# STM32N645xx register map
File version: 1.0
Registers are 32-bit, read-write, reset 0x0 unless marked. A register's access mark holds for its fields unless they carry their own. Offsets are from the block's base; [hi:lo] are bit positions; {n}, {i} and the like mark numbered series; 'fields as' and 'values as' point back to an identical list.

## DCMIPP
Base 0x48002000
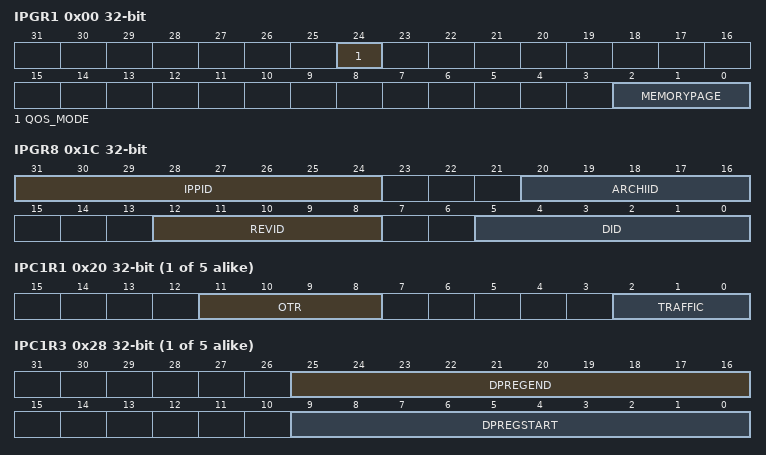
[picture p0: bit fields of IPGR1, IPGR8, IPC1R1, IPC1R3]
0x00 IPGR1 — DCMIPP IPPLUG global register 1
  [24] QOS_MODE — Quality of service
  [2:0] MEMORYPAGE — Memory page size, as power of 2 of 64-byte units:
0x04 IPGR2 — DCMIPP IPPLUG global register 2
  [0] PSTART — Request to lock the IP-Plug, to allow reconfiguration
0x08 IPGR3 — DCMIPP IPPLUG global register 3
  [0] IDLE — Status of IP-Plug
0x1C IPGR8 — DCMIPP IPPLUG identification register
  [31:24] IPPID — IP identifier (0xAA)
  [20:16] ARCHIID — Architecture identifier (0x04)
  [12:8] REVID — Revision identifier (0x03)
  [5:0] DID — Division identifier (0x14)
{0x10+0x10*i} IPC{i}R1 (i=1..5) — DCMIPP IPPLUG Clientx register 1
  [11:8] OTR — max outstanding transactions:
  [2:0] TRAFFIC — Burst size as power of 2 of 8 bytes units
{0x14+0x10*i} IPC{i}R2 (i=1..5) — DCMIPP IPPLUG Clientx register 2
  [19:16] WLRU — Ratio for WLRU[3:0] arbitration:
{0x18+0x10*i} IPC{i}R3 (i=1..5) — DCMIPP IPPLUG Clientx register 3
  [25:16] DPREGEND — End word (AXI width = 64 bits) of the FIFO of this client
  [9:0] DPREGSTART — Start word (AXI width = 64 bits) of the FIFO of this client
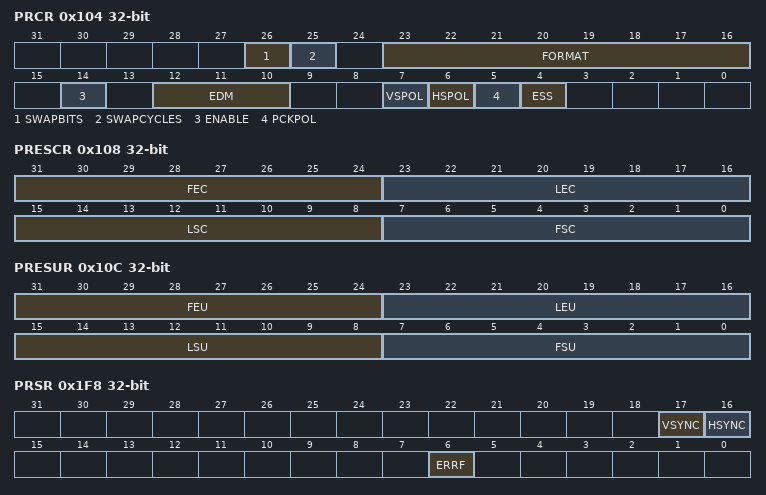
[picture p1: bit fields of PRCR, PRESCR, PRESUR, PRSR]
0x104 PRCR — DCMIPP parallel interface control register
  [26] SWAPBITS — Swap LSB vs
  [25] SWAPCYCLES — Swap data from cycle 0 vs
  [23:16] FORMAT — Other values: Data is captured and output as-is through the data/dump pipeline only (e
  [14] ENABLE — Parallel interface enable
  [12:10] EDM — Extended data mode
  [7] VSPOL — Vertical synchronization polarity
  [6] HSPOL — Horizontal synchronization polarity
  [5] PCKPOL — Pixel clock polarity
  [4] ESS — Embedded synchronization select
0x108 PRESCR — DCMIPP parallel interface embedded synchronization code register
  [31:24] FEC — Frame end delimiter code
  [23:16] LEC — Line end delimiter code
  [15:8] LSC — Line start delimiter code
  [7:0] FSC — Frame start delimiter code
0x10C PRESUR — DCMIPP parallel interface embedded synchronization unmask register
  [31:24] FEU — Frame end delimiter unmask
  [23:16] LEU — Line end delimiter unmask
  [15:8] LSU — Line start delimiter unmask
  [7:0] FSU — Frame start delimiter unmask
0x1F4 PRIER — DCMIPP parallel interface interrupt enable register
  [6] ERRIE — Synchronization error interrupt enable
0x1F8 PRSR — DCMIPP parallel interface status register
  [17] VSYNC — This bit gives the state of the VSYNC pin with the correct programmed polarity if the ENABLE bit is
  [16] HSYNC — This bit gives the state of the HSYNC pin with the correct programmed polarity if the ENABLE bit is
  [6] ERRF — Synchronization error raw interrupt status
0x1FC PRFCR — DCMIPP parallel interface interrupt clear register
  [6] CERRF — Synchronization error interrupt status clear
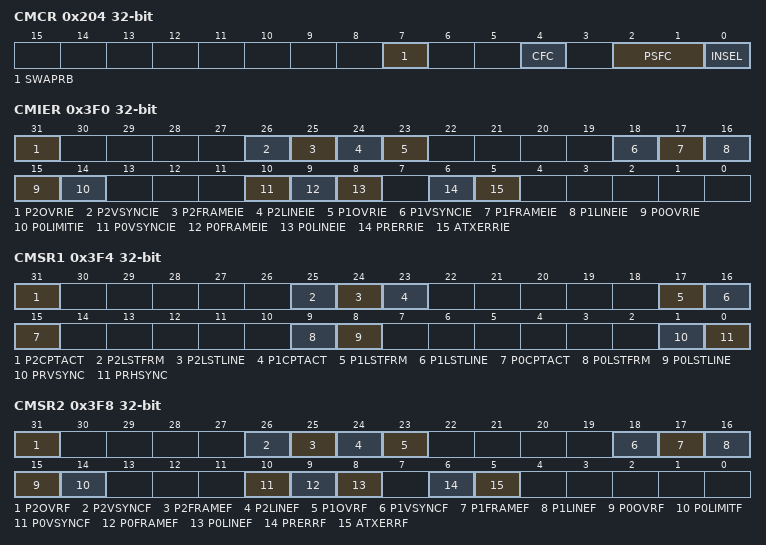
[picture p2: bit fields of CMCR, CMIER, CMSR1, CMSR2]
0x204 CMCR — DCMIPP common configuration register
  [7] SWAPRB — Swap R/U and B/V
  [4] CFC — Clear frame counter
  [2:1] PSFC — Pipe selection for the frame counter
  [0] INSEL — input selection
0x208 CMFRCR — DCMIPP common frame counter register
  [31:0] FRMCNT — Frame counter, read-only, loops around
0x3F0 CMIER — DCMIPP common interrupt enable register
  [31] P2OVRIE — Overrun interrupt status enable for the Pipe2
  [26] P2VSYNCIE — Vertical sync interrupt enable for the Pipe2
  [25] P2FRAMEIE — Frame Capture complete interrupt enable for the Pipe2
  [24] P2LINEIE — multi-Line Capture complete interrupt enable for the Pipe2
  [23] P1OVRIE — Overrun interrupt enable for the Pipe1
  [18] P1VSYNCIE — Vertical sync interrupt enable for the Pipe1
  [17] P1FRAMEIE — Frame Capture complete interrupt enable for the Pipe1
  [16] P1LINEIE — multi-Line Capture complete interrupt status clear for the Pipe1
  [15] P0OVRIE — Overrun interrupt enable for the Pipe0
  [14] P0LIMITIE — limit interrupt enable for the Pipe0
  [10] P0VSYNCIE — Vertical sync interrupt enable for the Pipe0
  [9] P0FRAMEIE — Frame Capture complete interrupt enable for the Pipe0
  [8] P0LINEIE — multi-Line Capture complete interrupt enable for the Pipe0
  [6] PRERRIE — limit interrupt enable for the Parallel Interface
  [5] ATXERRIE — AXI Transfer error interrupt enable for IPPLUG
0x3F4 CMSR1 — DCMIPP common status register 1
  [31] P2CPTACT — Active frame capture (active from start-of-frame to frame complete) for Pipe2
  [25] P2LSTFRM — Last frame LSB bit, sampled at frame capture complete event for Pipe2
  [24] P2LSTLINE — Last line LSB bit, sampled at Frame capture complete event for Pipe2
  [23] P1CPTACT — Active frame capture (active from start-of-frame to frame complete) for Pipe1
  [17] P1LSTFRM — Last frame LSB bit, sampled at frame capture complete event for Pipe1
  [16] P1LSTLINE — Last Line LSB bit, sampled at Frame capture complete event for Pipe1
  [15] P0CPTACT — Active frame capture (active from start-of-frame to frame complete) for Pipe0
  [9] P0LSTFRM — Last frame LSB bit, sampled at Frame capture complete event for Pipe0
  [8] P0LSTLINE — Last Line LSB bit, sampled at Frame capture complete event for Pipe0
  [1] PRVSYNC — This bit gives the state of the VSYNC pin with the correct programmed polarity on the parallel inte
  [0] PRHSYNC — This bit gives the state of the HSYNC pin with the correct programmed polarity on the parallel inte
0x3F8 CMSR2 — DCMIPP common status register 2
  [31] P2OVRF — Overrun raw interrupt status for Pipe2
  [26] P2VSYNCF — VSYNC raw interrupt status for Pipe2
  [25] P2FRAMEF — Frame capture completed raw interrupt status for Pipe2
  [24] P2LINEF — Multi-line capture completed raw interrupt status for Pipe2
  [23] P1OVRF — Overrun raw interrupt status for Pipe1
  [18] P1VSYNCF — VSYNC raw interrupt status for Pipe1
  [17] P1FRAMEF — Frame capture completed raw interrupt status for Pipe1
  [16] P1LINEF — Multi-line capture completed raw interrupt status for Pipe1
  [15] P0OVRF — Overrun raw interrupt status for Pipe0
  [14] P0LIMITF — Limit raw interrupt status for Pipe0
  [10] P0VSYNCF — VSYNC raw interrupt status for Pipe0
  [9] P0FRAMEF — Frame capture completed raw interrupt status for Pipe0
  [8] P0LINEF — Multi-line capture completed raw interrupt status for Pipe0
  [6] PRERRF — Synchronization error raw interrupt status for the parallel interface
  [5] ATXERRF — AXI transfer error interrupt status flag for the IPPLUG
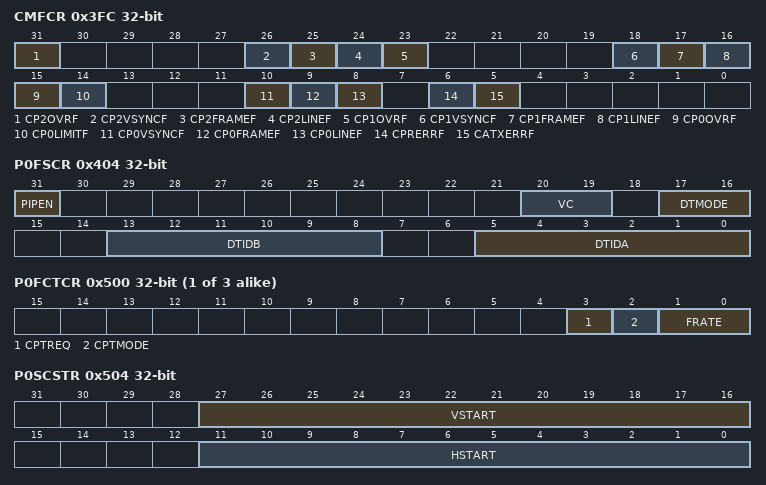
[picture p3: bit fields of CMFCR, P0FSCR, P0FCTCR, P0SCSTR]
0x3FC CMFCR — DCMIPP common interrupt clear register
  [31] CP2OVRF — Overrun interrupt status clear
  [26] CP2VSYNCF — Vertical synchronization interrupt status clear
  [25] CP2FRAMEF — Frame capture complete interrupt status clear
  [24] CP2LINEF — Multi-line capture complete interrupt status clear
  [23] CP1OVRF — Overrun interrupt status clear
  [18] CP1VSYNCF — Vertical synchronization interrupt status clear
  [17] CP1FRAMEF — Frame capture complete interrupt status clear
  [16] CP1LINEF — Multi-line capture complete interrupt status clear
  [15] CP0OVRF — Overrun interrupt status clear
  [14] CP0LIMITF — limit interrupt status clear
  [10] CP0VSYNCF — Vertical synchronization interrupt status clear
  [9] CP0FRAMEF — Frame capture complete interrupt status clear
  [8] CP0LINEF — Multi-line capture complete interrupt status clear
  [6] CPRERRF — Synchronization error interrupt status clear
  [5] CATXERRF — AXI Transfer error interrupt status clear
0x404 P0FSCR — DCMIPP Pipe0 flow selection configuration register
  [31] PIPEN — Activation of PipeN
  [20:19] VC — Flow selection mode
  [17:16] DTMODE — Flow selection mode
  [13:8] DTIDB — Data type selection ID B
  [5:0] DTIDA — Data type selection ID A
{0x500+0x400*i} P{i}FCTCR (i=0..2) — DCMIPP Pipe{i} flow control configuration register
  [3] CPTREQ — Capture requested
  [2] CPTMODE — Capture mode
  [1:0] FRATE — Frame capture rate control
0x504 P0SCSTR — DCMIPP Pipe0 stat/crop start register
  [27:16] VSTART — Vertical start, from 0 to 4094 pixels high
  [11:0] HSTART — Horizontal start, from 0 to 4094 words wide
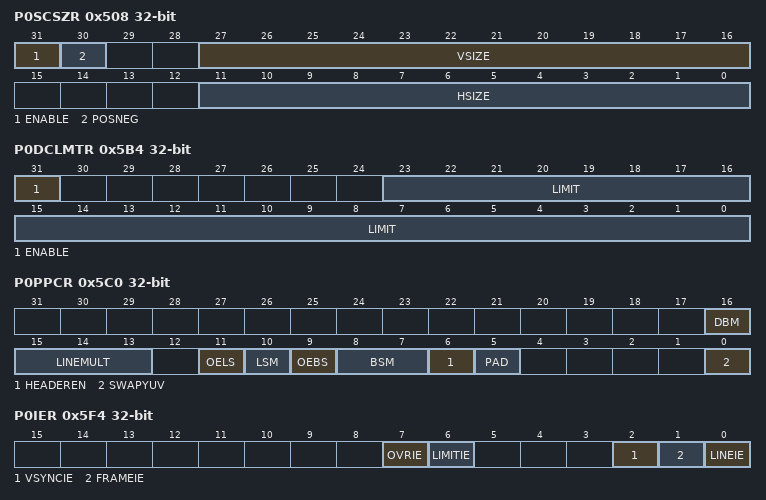
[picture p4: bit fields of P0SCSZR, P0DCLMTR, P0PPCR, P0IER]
0x508 P0SCSZR — DCMIPP Pipe0 stat/crop size register
  [31] ENABLE — This bit is set and cleared by software
  [30] POSNEG — This bit is set and cleared by software
  [27:16] VSIZE — Vertical size, from 0 to 4094 pixels high
  [11:0] HSIZE — Horizontal size, from 0 to 4094 word wide (data 32-bit)
0x5B0 P0DCCNTR — DCMIPP Pipe0 dump counter register
  [25:0] CNT — Number of data dumped during the frame
0x5B4 P0DCLMTR — DCMIPP Pipe0 dump limit register
  [31] ENABLE
  [23:0] LIMIT — Maximum number of 32-bit data that can be dumped during a frame, after the crop 2D operation
0x5C0 P0PPCR — DCMIPP Pipe0 pixel packer configuration register
  [16] DBM — Double buffer mode
  [15:13] LINEMULT — Amount of capture completed lines for LINE Event and Interrupt
  [11] OELS — Odd/even line select (line select start)
  [10] LSM — Line select mode
  [9] OEBS — Odd/even byte select (byte select start)
  [8:7] BSM — Byte select mode
  [6] HEADEREN — CSI header dump enable
  [5] PAD — Pad mode for monochrome and raw Bayer 10/12/14 bpp: MSB vs
  [0] SWAPYUV — SwapY vs UV bits, when the YUV mode is active
0x5C4 P0PPM0AR1 — DCMIPP Pipe0 pixel packer Memory0 address register 1
  [31:0] M0A — Memory0 address
0x5C8 P0PPM0AR2 — DCMIPP Pipe0 pixel packer Memory0 address register 2
  [31:0] M0A — Memory0 address
0x5D0 P0STM0AR — DCMIPP Pipe0 status Memory0 address register
0x5F4 P0IER — DCMIPP Pipe0 interrupt enable register
  [7] OVRIE — Overrun interrupt enable
  [6] LIMITIE — Limit interrupt enable
  [2] VSYNCIE — VSYNC interrupt enable
  [1] FRAMEIE — Frame capture completed interrupt enable
  [0] LINEIE — Multi-line capture completed interrupt enable
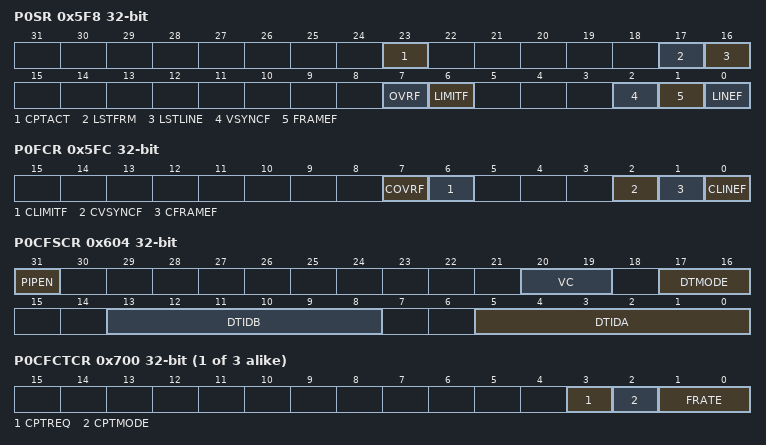
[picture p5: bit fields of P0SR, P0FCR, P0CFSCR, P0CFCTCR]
0x5F8 P0SR — DCMIPP Pipe0 status register
  [23] CPTACT — Capture immediate status
  [17] LSTFRM — Last frame LSB bit, sampled at frame capture complete event
  [16] LSTLINE — Last line LSB bit, sampled at frame capture complete event
  [7] OVRF — Overrun raw interrupt status
  [6] LIMITF — Limit raw interrupt status
  [2] VSYNCF — VSYNC raw interrupt status
  [1] FRAMEF — Frame capture completed raw interrupt status
  [0] LINEF — Multi-line capture completed raw interrupt status
0x5FC P0FCR — DCMIPP Pipe0 interrupt clear register
  [7] COVRF — Overrun interrupt status clear
  [6] CLIMITF — limit interrupt status clear
  [2] CVSYNCF — Vertical synchronization interrupt status clear
  [1] CFRAMEF — Frame capture complete interrupt status clear
  [0] CLINEF — Multi-line capture complete interrupt status clear
0x604 P0CFSCR — DCMIPP Pipe0 current flow selection configuration register
  [31] PIPEN — Current activation of PipeN
  [20:19] VC — Current flow selection mode
  [17:16] DTMODE — Flow selection mode
  [13:8] DTIDB — Current Data type selection ID B
  [5:0] DTIDA — Current Data type selection ID A
{0x700+0x400*i} P{i}CFCTCR (i=0..2) — DCMIPP Pipe{i} current flow control configuration register
  fields as P0FCTCR
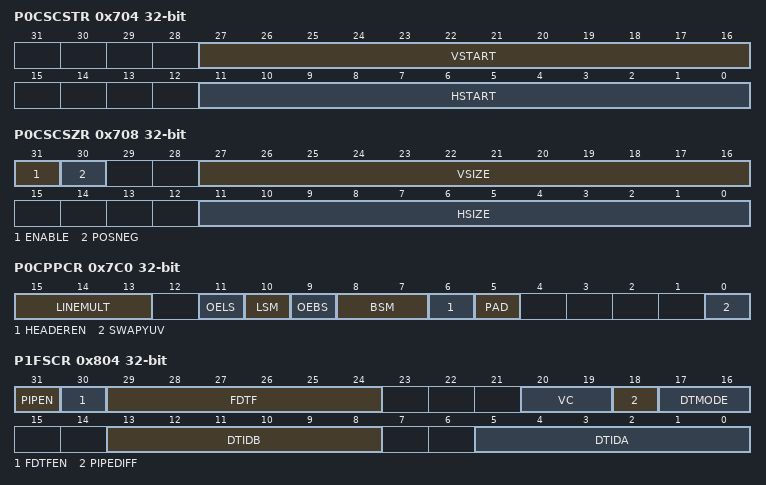
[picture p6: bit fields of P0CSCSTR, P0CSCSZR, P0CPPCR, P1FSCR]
0x704 P0CSCSTR — DCMIPP Pipe0 current stat/crop start register
  [27:16] VSTART — Current vertical start, from 0 to 4094 pixels high
  [11:0] HSTART — Current horizontal start, from 0 to 4094 words wide
0x708 P0CSCSZR — DCMIPP Pipe0 current stat/crop size register
  [31] ENABLE — Current value of the ENABLE bit
  [30] POSNEG — Current value of the POSNEG bit
  [27:16] VSIZE — Current vertical size, from 0 to 4094 pixels high
  [11:0] HSIZE — Current horizontal size, from 0 to 4094 word wide (data 32-bit)
0x7C0 P0CPPCR — DCMIPP Pipe0 current pixel packer configuration register
  [15:13] LINEMULT — Current amount of capture completed lines for LINE Event and Interrupt
  [11] OELS — Current odd/even line select (Line select start)
  [10] LSM — Current Line select mode
  [9] OEBS — Current odd/even byte select (Byte select start)
  [8:7] BSM — Current Byte select mode
  [6] HEADEREN — Current CSI header dump enable
  [5] PAD — Current Pad mode for monochrome and raw Bayer 10/12/14 bpp: MSB vs
  [0] SWAPYUV — SwapY vs UV bits, when the YUV mode is active
{0x7C4+0x400*i} P{i}CPPM0AR1 (i=0..2) — DCMIPP Pipe{i} current pixel packer Memory0 address register 1
  [31:0] M0A — Memory0 address
0x7C8 P0CPPM0AR2 — DCMIPP Pipe0 current pixel packer Memory0 address register 2
0x804 P1FSCR — DCMIPP Pipe1 flow selection configuration register
  [31] PIPEN — Activation of PipeN
  [30] FDTFEN — Force Data type format enable
  [29:24] FDTF — Force Data type format
  [20:19] VC — Flow selection mode
  [18] PIPEDIFF — Differentiates Pipe2 vs
  [17:16] DTMODE — Flow selection mode
  [13:8] DTIDB — Data type ID B
  [5:0] DTIDA — Data type ID A
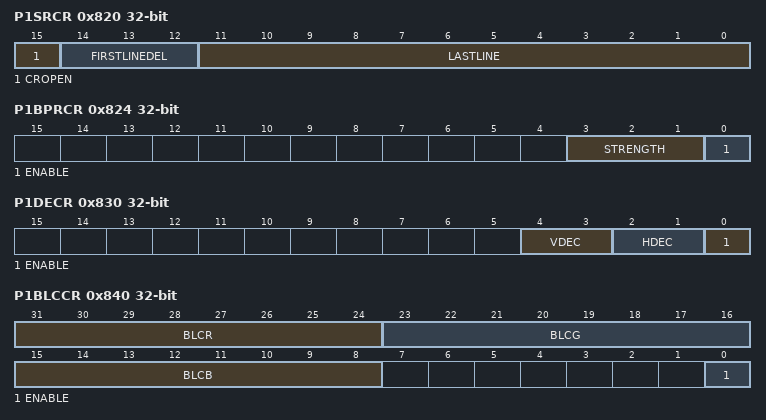
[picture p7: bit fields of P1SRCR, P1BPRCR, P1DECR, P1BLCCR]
0x820 P1SRCR — DCMIPP Pipe1 stat removal configuration register
  [15] CROPEN — Crop line enable
  [14:12] FIRSTLINEDEL — Number of lines to be deleted when CROPEN = 1
  [11:0] LASTLINE — Number of the last line to be kept when CROPEN = 1
0x824 P1BPRCR — DCMIPP Pipe1 bad pixel removal control register
  [3:1] STRENGTH — Strength (aggressivity) of the bad pixel detection:
  [0] ENABLE — Bad pixel detection must be enabled only for raw Bayer flows, as it corrupts RGB flows
0x828 P1BPRSR — DCMIPP Pipe1 bad pixel removal status register
  [11:0] BADCNT — Amount of detected bad pixels
0x830 P1DECR — DCMIPP Pipe1 decimation register
  [4:3] VDEC — Vertical decimation ratio
  [2:1] HDEC — Horizontal decimation ratio
  [0] ENABLE
0x840 P1BLCCR — DCMIPP Pipe1 black level calibration control register
  [31:24] BLCR — Black level calibration - Red
  [23:16] BLCG — Black level calibration - Green
  [15:8] BLCB — Black level calibration - Blue
  [0] ENABLE — Black level calibration
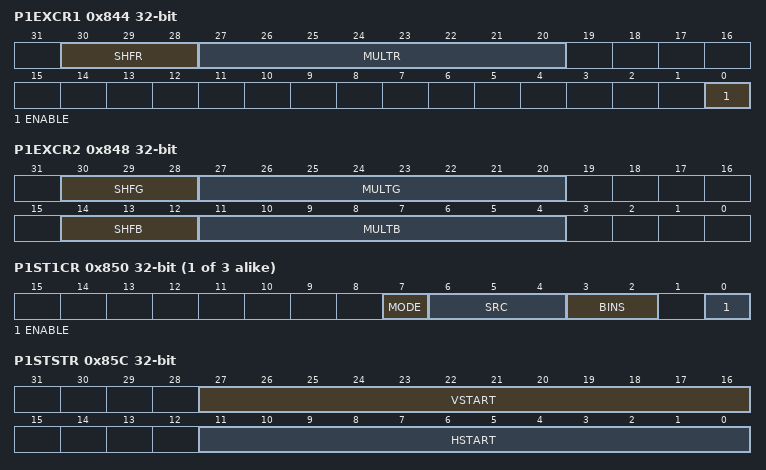
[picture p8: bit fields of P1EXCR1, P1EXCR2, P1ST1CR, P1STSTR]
0x844 P1EXCR1 — DCMIPP Pipe1 exposure control register 1
  [30:28] SHFR — Exposure shift - Red
  [27:20] MULTR — Exposure multiplier - Red
  [0] ENABLE — Exposure control (multiplication and shift) of all red, green and blue
0x848 P1EXCR2 — DCMIPP Pipe1 exposure control register 2
  [30:28] SHFG — Exposure shift - Green
  [27:20] MULTG — Exposure multiplier - Green
  [14:12] SHFB — Exposure shift - Blue
  [11:4] MULTB — Exposure multiplier - Blue
{0x84C+4i} P1ST{i}CR (i=1..3) — DCMIPP Pipe1 statistics {i} control register
  [7] MODE — Statistics mode
  [6:4] SRC — Statistics source
  [3:2] BINS — Bin definition
  [0] ENABLE
0x85C P1STSTR — DCMIPP Pipe1 statistics window start register
  [27:16] VSTART — Vertical start, from 0 to 4094 pixels high
  [11:0] HSTART — Horizontal start, from 0 to 4094 pixels wide
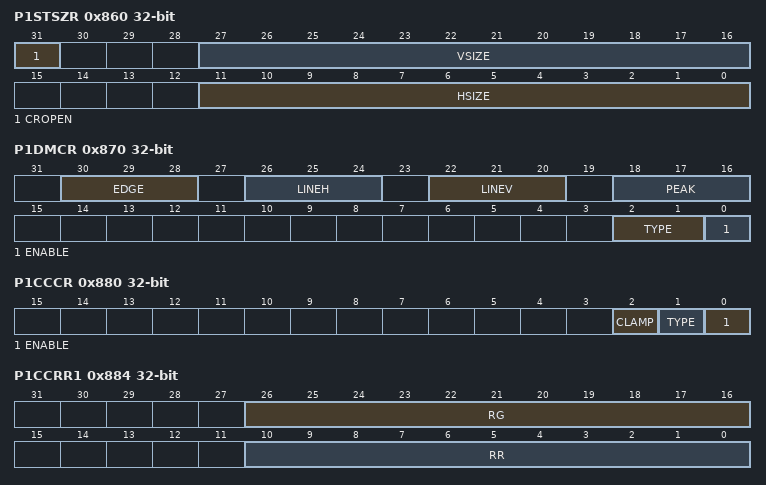
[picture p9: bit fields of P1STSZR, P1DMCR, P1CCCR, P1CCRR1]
0x860 P1STSZR — DCMIPP Pipe1 statistics window size register
  [31] CROPEN
  [27:16] VSIZE — Vertical size, from 0 to 4094 pixels high
  [11:0] HSIZE — Horizontal size, from 0 to 4094 pixels wide
0x864 P1ST1SR — DCMIPP Pipe1 statistics 1 status register
  [23:0] ACCU — Accumulation result, divided by 256
0x868 P1ST2SR — DCMIPP Pipe1 statistics 2 status register
  [23:0] ACCU — accumulation result, divided by 256
0x86C P1ST3SR — DCMIPP Pipe1 statistics 3 status register
  [23:0] ACCU — accumulation result, divided by 256
0x870 P1DMCR — DCMIPP Pipe1 demosaicing configuration register
  [30:28] EDGE — Strength of the edge detection
  [26:24] LINEH — Strength of the horizontal line detection
  [22:20] LINEV — Strength of the vertical line detection
  [18:16] PEAK — Strength of the peak detection
  [2:1] TYPE — Raw Bayer type
  [0] ENABLE
0x880 P1CCCR — DCMIPP Pipe1 ColorConv configuration register
  [2] CLAMP — Clamp the output samples
  [1] TYPE — output samples type used while CLAMP is activated
  [0] ENABLE
0x884 P1CCRR1 — DCMIPP Pipe1 ColorConv red coefficient register 1
  [26:16] RG — Coefficient row 1 column 2 of the matrix
  [10:0] RR — Coefficient row 1 column 1 of the matrix
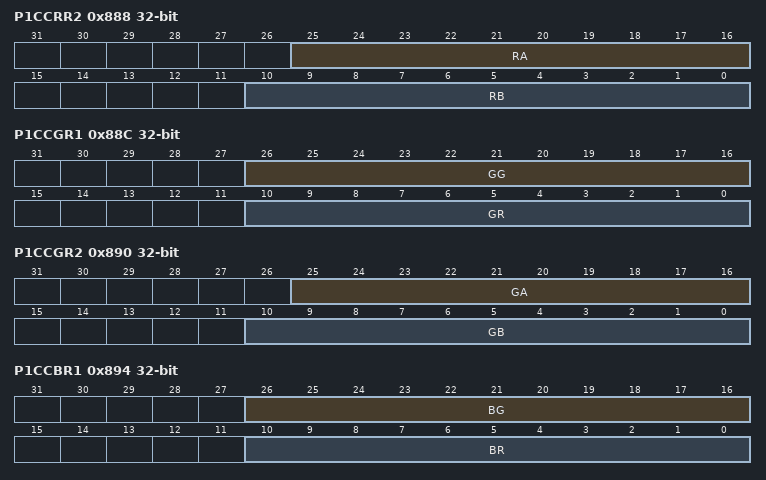
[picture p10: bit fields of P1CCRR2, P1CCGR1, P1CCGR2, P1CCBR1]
0x888 P1CCRR2 — DCMIPP Pipe1 ColorConv red coefficient register 2
  [25:16] RA — Coefficient row 1 of the added column (signed integer value)
  [10:0] RB — Coefficient row 1 column 3 of the matrix
0x88C P1CCGR1 — DCMIPP Pipe1 ColorConv green coefficient register 1
  [26:16] GG — Coefficient row 2 column 2 of the matrix
  [10:0] GR — Coefficient row 2 column 1 of the matrix
0x890 P1CCGR2 — DCMIPP Pipe1 ColorConv green coefficient register 2
  [25:16] GA — Coefficient row 2 of the added column (signed integer value)
  [10:0] GB — Coefficient row 2 column 3 of the matrix
0x894 P1CCBR1 — DCMIPP Pipe1 ColorConv blue coefficient register 1
  [26:16] BG — Coefficient row 3 column 2 of the matrix
  [10:0] BR — Coefficient row 3 column 1 of the matrix
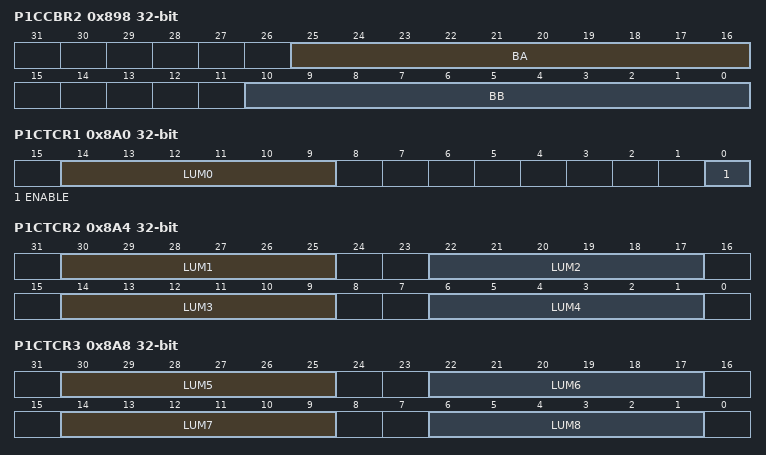
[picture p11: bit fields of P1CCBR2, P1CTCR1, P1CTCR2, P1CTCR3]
0x898 P1CCBR2 — DCMIPP Pipe1 ColorConv blue coefficient register 2
  [25:16] BA — Coefficient row 3 of the added column (signed integer value)
  [10:0] BB — Coefficient row 3 column 3 of the matrix
0x8A0 P1CTCR1 — DCMIPP Pipe1 contrast control register 1
  [14:9] LUM0 — Luminance increase for input luminance of 0 (increase is idle with LUMx = 16)
  [0] ENABLE
0x8A4 P1CTCR2 — DCMIPP Pipe1 contrast control register 2
  [38-8n:33-8n] LUM{n} (n=1..4) — Luminance increase for input luminance of {32n} (increase is idle with LUMx = 16)
0x8A8 P1CTCR3 — DCMIPP Pipe1 contrast control register 3
  [70-8n:65-8n] LUM{n} (n=5..8) — Luminance increase for input luminance of {32n} (increase is idle with LUMx = 16)
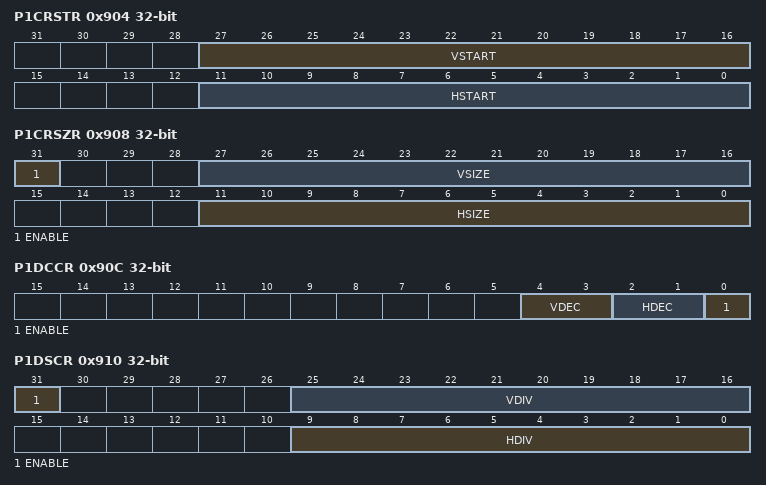
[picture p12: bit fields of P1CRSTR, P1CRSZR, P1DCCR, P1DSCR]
0x904 P1CRSTR — DCMIPP Pipe1 crop window start register
  fields as P1STSTR
0x908 P1CRSZR — DCMIPP Pipe1 crop window size register
  [31] ENABLE
  [27:16] VSIZE — Vertical size, from 0 to 4094 pixels high
  [11:0] HSIZE — Horizontal size, from 0 to 4094 pixels wide
0x90C P1DCCR — DCMIPP Pipe1 decimation register
  [4:3] VDEC — Vertical decimation ratio
  [2:1] HDEC — Horizontal decimation ratio
  [0] ENABLE — Decimation enable
0x910 P1DSCR — DCMIPP Pipe1 downsize configuration register
  [31] ENABLE — Downscaler Enable
  [25:16] VDIV — Vertical division factor, from 128 (8x) to 1023 (1x)
  [9:0] HDIV — Horizontal division factor, from 128 (8x) to 1023 (1x)
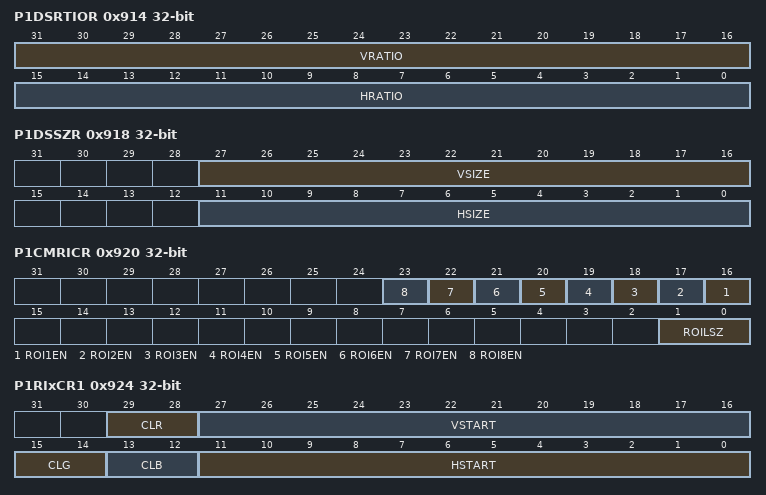
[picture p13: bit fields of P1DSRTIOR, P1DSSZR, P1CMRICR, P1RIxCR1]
0x914 P1DSRTIOR — DCMIPP Pipe1 downsize ratio register
  [31:16] VRATIO — Vertical ratio, from 8192 (1x) to 65535 (8x)
  [15:0] HRATIO — Horizontal ratio, from 8192 (1x) to 65535 (8x)
0x918 P1DSSZR — DCMIPP Pipe1 downsize destination size register
  [27:16] VSIZE — Vertical size, from 0 to 4094 pixels high
  [11:0] HSIZE — Horizontal size, from 0 to 4094 pixels wide
0x920 P1CMRICR — DCMIPP Pipe1 common ROI configuration register
  [n+15] ROI{n}EN (n=1..8) — Region Of Interest {n} Enable
  [1:0] ROILSZ — Region of interest line size width
0x924 P1RIxCR1 — DCMIPP Pipe1 ROIx configuration register 1
  [29:28] CLR — Color line red
  [27:16] VSTART — Vertical start
  [15:14] CLG — Color line green
  [13:12] CLB — Color line blue
  [11:0] HSTART — Horizontal start
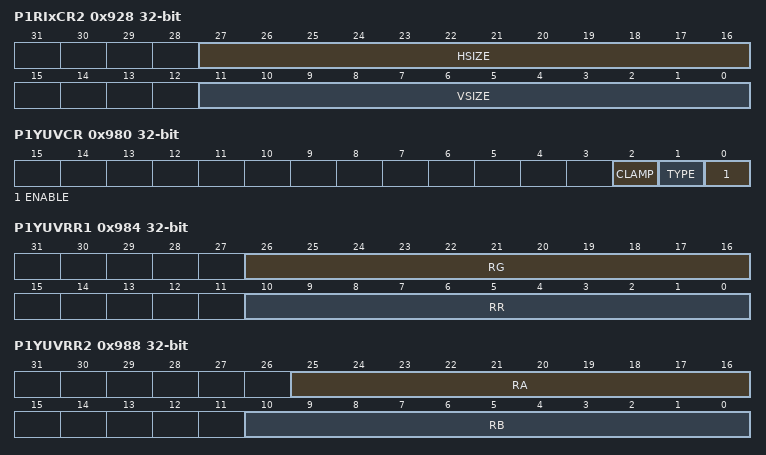
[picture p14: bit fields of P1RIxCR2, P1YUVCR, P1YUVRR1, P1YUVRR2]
0x928 P1RIxCR2 — DCMIPP Pipe1 ROIx configuration register 2
  [27:16] HSIZE — Horizontal Size
  [11:0] VSIZE — Vertical Size
0x970 P1GMCR — DCMIPP Pipe1 gamma configuration register
  [0] ENABLE — Gamma enable
0x980 P1YUVCR — DCMIPP Pipe1 YUVConv configuration register
  [2] CLAMP — Clamp the output samples
  [1] TYPE — Output samples type used while CLAMP is activated
  [0] ENABLE
0x984 P1YUVRR1 — DCMIPP Pipe1 YUVConv red coefficient register 1
  fields as P1CCRR1
0x988 P1YUVRR2 — DCMIPP Pipe1 YUVConv red coefficient register 2
  fields as P1CCRR2
0x98C P1YUVGR1 — DCMIPP Pipe1 YUVConv green coefficient register 1
  fields as P1CCGR1
0x990 P1YUVGR2 — DCMIPP Pipe1 YUVConv green coefficient register 2
  fields as P1CCGR2
0x994 P1YUVBR1 — DCMIPP Pipe1 YUVConv blue coefficient register 1
  fields as P1CCBR1
0x998 P1YUVBR2 — DCMIPP Pipe1 YUV blue coefficient register 2
  fields as P1CCBR2
0x9C0 P1PPCR — DCMIPP Pipe1 pixel packer configuration register
  [20] LMAWE — Line multi address wrapping enable
  [19:17] LMAWM — Line multi address wrapping modulo
  [16] DBM — Double buffer mode
  [15:13] LINEMULT — Amount of capture completed lines for LINE Event and Interrupt
  [4] SWAPRB — Swaps R-vs-B components if RGB, and U-vs-V components if YUV
  [3:0] FORMAT — Memory format
0x9C4 P1PPM0AR1 — DCMIPP Pipe1 pixel packer Memory0 address register 1
  [31:0] M0A — Memory0 address register 1
0x9C8 P1PPM0AR2 — DCMIPP Pipe1 pixel packer Memory0 address register 2
  [31:0] M0A — Memory0 address register 2
0x9CC P1PPM0PR — DCMIPP Pipe1 pixel packer Memory0 pitch register
  [14:0] PITCH — Number of bytes between the address of two consecutive lines
0x9D0 P1STM0AR — DCMIPP Pipe1 status Memory0 address register
0x9D4 P1PPM1AR1 — DCMIPP Pipe1 pixel packer Memory1 address register 1
  [31:0] M1A — Memory1 address
0x9D8 P1PPM1AR2 — DCMIPP Pipe1 pixel packer Memory1 address register 2
  [31:0] M1A — Memory1 address
0x9DC P1PPM1PR — DCMIPP Pipe1 pixel packer Memory1 pitch register
  fields as P1PPM0PR
0x9E0 P1STM1AR — DCMIPP Pipe1 status Memory1 address register
  [14:0] M1A — status Memory1 address register
0x9E4 P1PPM2AR1 — DCMIPP Pipe1 pixel packer memory2 address register 1
  [31:0] M2A — Memory2 address register 1
0x9E8 P1PPM2AR2 — DCMIPP Pipe1 pixel packer memory2 address register 2
  [31:0] M2A — Memory2 address register 2
0x9F0 P1STM2AR — DCMIPP Pipe1 status Memory2 address register
  [31:0] M2A — status Memory2 address register
0x9F4 P1IER — DCMIPP Pipe1 interrupt enable register
  [7] OVRIE — Overrun interrupt enable
  [2] VSYNCIE — VSYNC interrupt enable
  [1] FRAMEIE — Frame capture completed interrupt enable
  [0] LINEIE — Multi-line capture completed interrupt enable
0x9F8 P1SR — DCMIPP Pipe1 status register
  [23] CPTACT — Capture immediate status
  [17] LSTFRM — Last frame LSB bit, sampled at frame capture complete event
  [16] LSTLINE — Last line LSB bit, sampled at frame capture complete event
  [7] OVRF — Overrun raw interrupt status
  [2] VSYNCF — VSYNC raw interrupt status
  [1] FRAMEF — Frame capture completed raw interrupt status
  [0] LINEF — Multi-line capture completed raw interrupt status
0x9FC P1FCR — DCMIPP Pipe1 interrupt clear register
  [7] COVRF — Overrun interrupt status clear
  [2] CVSYNCF — Vertical synchronization interrupt status clear
  [1] CFRAMEF — Frame capture complete interrupt status clear
  [0] CLINEF — Multi-line capture complete interrupt status clear
0xA04 P1CFSCR — DCMIPP Pipe1 current flow selection configuration register
  [31] PIPEN — Current activation of PipeN
  [30] FDTFEN — Current force Data type format enable
  [29:24] FDTF — Current force Data type format
  [20:19] VC — Current flow selection mode
  [18] PIPEDIFF — Current differentiates Pipe2 vs
  [17:16] DTMODE — Flow selection mode
  [13:8] DTIDB — Current Data type ID B
  [5:0] DTIDA — Current Data type ID A
0xA24 P1CBPRCR — DCMIPP Pipe1 current bad pixel removal register
  [3:1] STRENGTH — Current strength (aggressivity) of the bad pixel detection:
  [0] ENABLE — Current status of enable bit
0xA40 P1CBLCCR — DCMIPP Pipe1 current black level calibration control register
  [31:24] BLCR — Current black level calibration - Red
  [23:16] BLCG — Current black level calibration - Green
  [15:8] BLCB — Current black level calibration - Blue
  [0] ENABLE — For current black level calibration
0xA44 P1CEXCR1 — DCMIPP Pipe1 current exposure control register 1
  [30:28] SHFR — Current exposure shift - Red
  [27:20] MULTR — Current exposure multiplier - Red
  [0] ENABLE — for exposure control (multiplication and shift)
0xA48 P1CEXCR2 — DCMIPP Pipe1 current exposure control register 2
  [30:28] SHFG — Current exposure shift - Green
  [27:20] MULTG — Current exposure multiplier - Green
  [14:12] SHFB — Current exposure shift - Blue
  [11:4] MULTB — Current exposure multiplier - Blue
0xA50 P1CST1CR — DCMIPP Pipe1 current statistics 1 control register
  [31:8] ACCU — Current accumulation result, divided by 256
  [7] MODE — Current statistics mode
  [6:4] SRC — Current source of statistics
  [3:2] BINS — Current bin definition
  [0] ENABLE — Current enable bit value
0xA54 P1CST2CR — DCMIPP Pipe1 current statistics 2 control register
  [31:8] ACCU — Accumulation result, divided by 256
  [7] MODE — statistics mode
  [6:4] SRC — source of stat
  [3:2] BINS — Bin definition
  [0] ENABLE
0xA58 P1CST3CR — DCMIPP Pipe1 current statistics 3 control register
  [31:8] ACCU — Accumulation result, divided by 256
  [7] MODE — Statistics mode
  [6:4] SRC — Statistics source
  [3:2] BINS — Bin definition
  [0] ENABLE
0xA5C P1CSTSTR — DCMIPP Pipe1 current statistics window start register
  [27:16] VSTART — Current vertical start, from 0 to 4094 pixels high
  [11:0] HSTART — Current horizontal start, from 0 to 4094 pixels wide
0xA60 P1CSTSZR — DCMIPP Pipe1 current statistics window size register
  [31] CROPEN — Current CROPEN bit value
  [27:16] VSIZE — Current vertical size, from 0 to 4094 pixels high
  [11:0] HSIZE — Current horizontal size, from 0 to 4094 pixels wide
0xA80 P1CCCCR — DCMIPP Pipe1 current ColorConv configuration register
  [2] CLAMP — Clamp the output samples
  [1] TYPE — output samples type used while CLAMP is activated
  [0] ENABLE — This bit indicates the current value applied
0xA84 P1CCCRR1 — DCMIPP Pipe1 current ColorConv red coefficient register 1
  [26:16] RG — Current coefficient row 1 column 2 of the matrix
  [10:0] RR — Current coefficient row 1 column 1 of the matrix
0xA88 P1CCCRR2 — DCMIPP Pipe1 current ColorConv red coefficient register 2
  [25:16] RA — Current coefficient row 1 of the added column (signed integer value)
  [10:0] RB — Current coefficient row 1 column 3 of the matrix
0xA8C P1CCCGR1 — DCMIPP Pipe1 current ColorConv green coefficient register 1
  [26:16] GG — Current coefficient row 2 column 2 of the matrix
  [10:0] GR — Current coefficient row 2 column 1 of the matrix
0xA90 P1CCCGR2 — DCMIPP Pipe1 current ColorConv green coefficient register 2
  [25:16] GA — Current coefficient row 2 of the added column (signed integer value)
  [10:0] GB — Current coefficient row 2 column 3 of the matrix
0xA94 P1CCCBR1 — DCMIPP Pipe1 current ColorConv blue coefficient register 1
  [26:16] BG — Current coefficient row 3 column 2 of the matrix
  [10:0] BR — Current coefficient row 3 column 1 of the matrix
0xA98 P1CCCBR2 — DCMIPP Pipe1 current ColorConv blue coefficient register 2
  [25:16] BA — Current coefficient row 3 of the added column (signed integer value)
  [10:0] BB — Current coefficient row 3 column 3 of the matrix
0xAA0 P1CCTCR1 — DCMIPP Pipe1 current contrast control register 1
  [14:9] LUM0 — Current luminance increase for input luminance of 0 (increase is idle with LUMx = 16)
  [0] ENABLE — Current ENABLE bit value
0xAA4 P1CCTCR2 — DCMIPP Pipe1 current contrast control register 2
  [38-8n:33-8n] LUM{n} (n=1..4) — Current luminance increase for input luminance of {32n} (increase is idle with LUMx = 16)
0xAA8 P1CCTCR3 — DCMIPP Pipe1 current contrast control register 3
  fields as P1CTCR3
0xB04 P1CCRSTR — DCMIPP Pipe1 current crop window start register
  fields as P1CSTSTR
0xB08 P1CCRSZR — DCMIPP Pipe1 current crop window size register
  [31] ENABLE — Current ENABLE bit value
  [27:16] VSIZE — Current vertical size, from 0 to 4094 pixels high
  [11:0] HSIZE — Current horizontal size, from 0 to 4094 pixels wide
0xB0C P1CDCCR — DCMIPP Pipe1 current decimation register
  fields as P1DCCR
0xB10 P1CDSCR — DCMIPP Pipe1 current downsize configuration register
  [31] ENABLE — Current value of the bit ENABLE
  [25:16] VDIV — Current vertical division factor, from 128 (8x) to 1023 (1x)
  [9:0] HDIV — Current horizontal division factor, from 128 (8x) to 1023 (1x)
0xB14 P1CDSRTIOR — DCMIPP Pipe1 current downsize ratio register
  [31:16] VRATIO — Current vertical ratio, from 8192 (1x) to 65535 (8x)
  [15:0] HRATIO — Current horizontal ratio, from 8192 (1x) to 65535 (8x)
0xB18 P1CDSSZR — DCMIPP Pipe1 current downsize destination size register
  [27:16] VSIZE — Current vertical size, from 0 to 4094 pixels high
  [11:0] HSIZE — Current horizontal size, from 0 to 4094 pixels wide
0xB20 P1CCMRICR — DCMIPP Pipe1 current common ROI configuration register
0xB24 P1CRIxCR1 — DCMIPP Pipe1 current ROIx configuration register 1
0xB28 P1CRIxCR2 — DCMIPP Pipe1 current ROIx configuration register 2
0xBC0 P1CPPCR — DCMIPP Pipe1 current pixel packer configuration register
  [15:13] LINEMULT — Amount of capture completed lines for LINE Event and Interrupt
  [4] SWAPRB — Swaps R-vs-B components if RGB, and U-vs-V components if YUV
  [3:0] FORMAT — Memory format
0xBC8 P1CPPM0AR2 — DCMIPP Pipe1 current pixel packer Memory0 address register 1
0xBCC P1CPPM0PR — DCMIPP Pipe1 current pixel packer Memory0 pitch register
  fields as P1PPM0PR
0xBD4 P1CPPM1AR1 — DCMIPP Pipe1 current pixel packer Memory1 address register 1
  [31:0] M1A — Memory1 address
0xBD8 P1CPPM1AR2 — DCMIPP Pipe1 current pixel packer Memory1 address register 2
0xBDC P1CPPM1PR — DCMIPP Pipe1 current pixel packer Memory1 pitch register
  fields as P1PPM0PR
0xBE4 P1CPPM2AR1 — DCMIPP Pipe1 current pixel packer memory2 address register 1
  [31:0] M2A — Memory 2 address
0xBE8 P1CPPM2AR2 — DCMIPP Pipe1 current pixel packer Memory2 address register 2
0xC04 P2FSCR — DCMIPP Pipe2 flow selection configuration register
  [31] PIPEN — Activation of PipeN
  [30] FDTFEN — Force Data type format enable
  [29:24] FDTF — Force Data type format
  [20:19] VC — Flow selection mode
  [5:0] DTIDA — Data type ID
0xD04 P2CRSTR — DCMIPP Pipe2 crop window start register
  fields as P1STSTR
0xD08 P2CRSZR — DCMIPP Pipe2 crop window size register
  fields as P1CRSZR
0xD0C P2DCCR — DCMIPP Pipe2 decimation register
  fields as P1DCCR
0xD10 P2DSCR — DCMIPP Pipe2 downsize configuration register
  [31] ENABLE
  [25:16] VDIV — Vertical division factor, from 128 (8x) to 1023 (1x)
  [9:0] HDIV — Horizontal division factor, from 128 (8x) to 1023 (1x)
0xD14 P2DSRTIOR — DCMIPP Pipe2 downsize ratio register
  fields as P1DSRTIOR
0xD18 P2DSSZR — DCMIPP Pipe2 downsize destination size register
  fields as P1DSSZR
0xD20 P2CMRICR — DCMIPP Pipe2 common ROI configuration register
  fields as P1CMRICR
0xD24 P2RIxCR1 — DCMIPP Pipe2 ROIx configuration register 1
  fields as P1RIxCR1
0xD28 P2RIxCR2 — DCMIPP Pipe2 ROIx configuration register 2
  [27:16] HSIZE — Horizontal Size
  [11:0] VSIZE — Vertical Size
0xD70 P2GMCR — DCMIPP Pipe2 gamma configuration register
  [0] ENABLE
0xDC0 P2PPCR — DCMIPP Pipe2 pixel packer configuration register
  [22:20] LMAWE — Line multi address wrapping enable
  [19:17] LMAWM — Line multi address wrapping modulo
  [16] DBM — Double buffer mode
  [15:13] LINEMULT — Amount of capture completed lines for LINE Event and Interrupt
  [4] SWAPRB — Swaps R-vs-B components if RGB, and if YUV, swaps U-vs-V components
  [3:0] FORMAT — Memory format (only coplanar formats are supported in Pipe2)
0xDC4 P2PPM0AR1 — DCMIPP Pipe2 pixel packer Memory0 address register 1
  [31:0] M0A — Memory0 address register 1
0xDC8 P2PPM0AR2 — DCMIPP Pipe2 pixel packer Memory0 address register 2
  [31:0] M0A — Memory0 address register 2
0xDCC P2PPM0PR — DCMIPP Pipe2 pixel packer Memory0 pitch register
  fields as P1PPM0PR
0xDD0 P2STM0AR — DCMIPP Pipe2 status Memory0 address register
  [31:0] P2STM0AR — Pipe2 status Memory0 address register
0xDF4 P2IER — DCMIPP Pipe2 interrupt enable register
  fields as P1IER
0xDF8 P2SR — DCMIPP Pipe2 status register
  fields as P1SR
0xDFC P2FCR — DCMIPP Pipe2 interrupt clear register
  fields as P1FCR
0xE04 P2CFSCR — DCMIPP Pipe2 current flow selection configuration register
  [31] PIPEN — Current activation of PipeN
  [30] FDTFEN — Current force Data type format enable
  [29:24] FDTF — Current force Data type format
  [20:19] VC — Current flow selection mode
  [5:0] DTID — Current Data type ID
0xF04 P2CCRSTR — DCMIPP Pipe2 current crop window start register
  fields as P1CSTSTR
0xF08 P2CCRSZR — DCMIPP Pipe2 current crop window size register
  fields as P1CCRSZR
0xF0C P2CDCCR — DCMIPP Pipe2 current decimation register
  fields as P1DCCR
0xF10 P2CDSCR — DCMIPP Pipe2 current downsize configuration register
  fields as P1CDSCR
0xF14 P2CDSRTIOR — DCMIPP Pipe2 current downsize ratio register
  fields as P1CDSRTIOR
0xF18 P2CDSSZR — DCMIPP Pipe2 current downsize destination size register
  fields as P1CDSSZR
0xF24 P2CRIxCR1 — Pipe2 current ROIx configuration register 1
0xF28 P2CRIxCR2 — Pipe2 current ROIx configuration register 2
0xFC0 P2CPPCR — DCMIPP Pipe2 current pixel packer configuration register
  fields as P2PPCR
0xFC8 P2CPPM0AR2 — DCMIPP Pipe2 current pixel packer Memory0 address register 2
  [31:0] M0A — Memory0 address Register 2
0xFCC P2CPPM0PR — DCMIPP Pipe2 current pixel packer Memory0 pitch register
  fields as P1PPM0PR
0xFEC HWCFGR2 — DCMIPP hardware configuration register 2
  [28] STV — Statistic Version
  [24] TPG — Test Pattern Generator
  [20] MCU — Macroblock unit as pixel format
  [17] DEC2 — Decimation on Pipe2 before downsize
  [16] DEC1 — Decimation on Pipe1 before downsize
  [12] ADDMOD — Address modulo computation to access a small buffer in streaming featured
  [8] PROCCLK — Processing clock linked to AXI clock featured
  [4] DBMFT — Double buffer mode featured
  [2:0] VPFT — Virtual pipe function
0xFF0 HWCFGR1 — DCMIPP hardware configuration register 1
  [31:28] ROI2NB — Number of ROIs for Pipe2
  [27:24] ROI1NB — Number of ROIs for Pipe1
  [21:20] PLANARFT — Buffer features for Pipe1
  [16] RB2RGB — Raw Bayer to RGB feature (demosaicer)
  [13] DSP2FT — Down-sampling feature for the pixel Pipe2
  [12] DSP1FT — Down-sampling feature for the pixel Pipe1
  [8] IPPLUGCFG — IP-Plug configuration
  [5:4] PIPENB — Number of pipes
  [0] CSIFT — CSI2 host protocol compliant
0xFF4 VERR — DCMIPP version register
  [7:4] MAJREV — DCMIPP major revision
  [3:0] MINREV — DCMIPP minor revision
0xFF8 IPIDR — DCMIPP identification register
  [31:0] IDR — Parallel camera interface (DCMI) and optional pixel processing (PP)
0xFFC SIDR — DCMIPP size identification register
  [31:0] SID — 4-Kbyte decoding space
